# STM32F446x register map
File version: 1.0
Registers are 32-bit, read-write, reset 0x0 unless marked. A register's access mark holds for its fields unless they carry their own. Offsets are from the block's base; [hi:lo] are bit positions; {n}, {i} and the like mark numbered series.

## OTG_FS_PWRCLK — USB on the go full speed
Base 0x50000E00
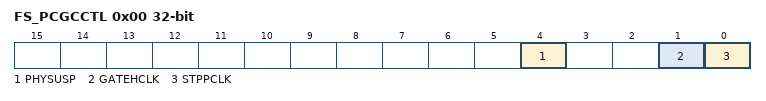
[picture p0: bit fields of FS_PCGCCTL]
0x00 FS_PCGCCTL — OTG_FS power and clock gating control register (OTG_FS_PCGCCTL)
  [4] PHYSUSP — PHY Suspended
  [1] GATEHCLK
  [0] STPPCLK — Stop PHY clock

## NVIC — Nested Vectored Interrupt Controller
Base 0xE000E000
0x04 ICTR ro — Interrupt Controller Type Register
  [3:0] INTLINESNUM — Total number of interrupt lines in groups
{0x100+4i} ISER{i} (i=0..2) — Interrupt Set-Enable Register
  [31:0] SETENA
{0x180+4i} ICER{i} (i=0..2) — Interrupt Clear-Enable Register
  [31:0] CLRENA
{0x200+4i} ISPR{i} (i=0..2) — Interrupt Set-Pending Register
  [31:0] SETPEND
{0x280+4i} ICPR{i} (i=0..2) — Interrupt Clear-Pending Register
  [31:0] CLRPEND
{0x300+4i} IABR{i} ro (i=0..2) — Interrupt Active Bit Register
  [31:0] ACTIVE
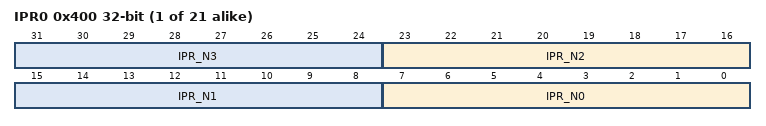
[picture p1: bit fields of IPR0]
{0x400+4i} IPR{i} (i=0..20) — Interrupt Priority Register
  [8n+7:8n] IPR_N{n} (n=0..3)
0xF00 STIR wo — Software Triggered Interrupt Register
  [8:0] INTID — interrupt to be triggered

## FLASH
Base 0x40023C00
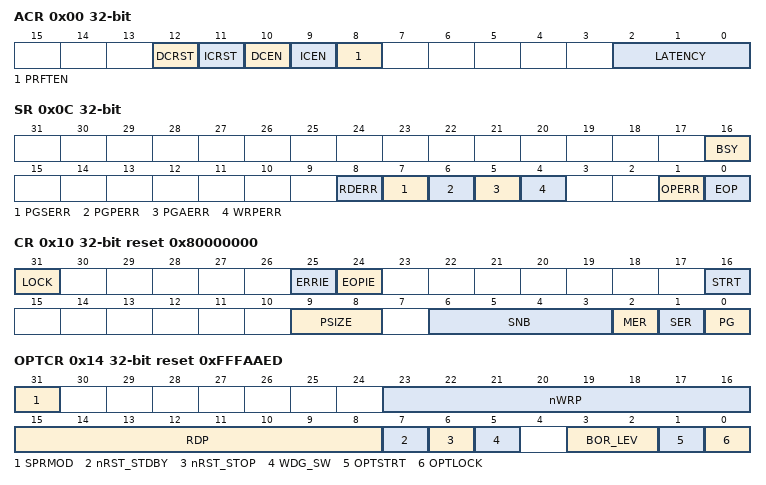
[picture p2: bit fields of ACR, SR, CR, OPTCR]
0x00 ACR access per field — Flash access control register
  [12] DCRST rw — Data cache reset
  [11] ICRST wo — Instruction cache reset
  [10] DCEN rw — Data cache enable
  [9] ICEN rw — Instruction cache enable
  [8] PRFTEN rw — Prefetch enable
  [2:0] LATENCY rw
0x04 KEYR wo — Flash key register
  [31:0] KEY — FPEC key
0x08 OPTKEYR wo — Flash option key register
  [31:0] OPTKEY — Option byte key
0x0C SR access per field — Status register
  [16] BSY ro — Busy
  [8] RDERR rw — Read Protection Error
  [7] PGSERR rw — Programming sequence error
  [6] PGPERR rw — Programming parallelism error
  [5] PGAERR rw — Programming alignment error
  [4] WRPERR rw — Write protection error
  [1] OPERR rw — Operation error
  [0] EOP rw — End of operation
0x10 CR reset 0x80000000 — Control register
  [31] LOCK
  [25] ERRIE — Error interrupt enable
  [24] EOPIE — End of operation interrupt enable
  [16] STRT — Start
  [9:8] PSIZE — Program size
  [6:3] SNB — Sector number
  [2] MER — Mass Erase of sectors 0 to 11
  [1] SER — Sector Erase
  [0] PG — Programming
0x14 OPTCR reset 0xFFFAAED — Flash option control register
  [31] SPRMOD — Selection of Protection Mode of nWPRi bits
  [23:16] nWRP — Not write protect
  [15:8] RDP — Read protect
  [7] nRST_STDBY — nRST_STDBY User option bytes
  [6] nRST_STOP — nRST_STOP User option bytes
  [5] WDG_SW — WDG_SW User option bytes
  [3:2] BOR_LEV — BOR reset Level
  [1] OPTSTRT — Option start
  [0] OPTLOCK — Option lock

## EXTI — External interrupt/event controller
Base 0x40013C00
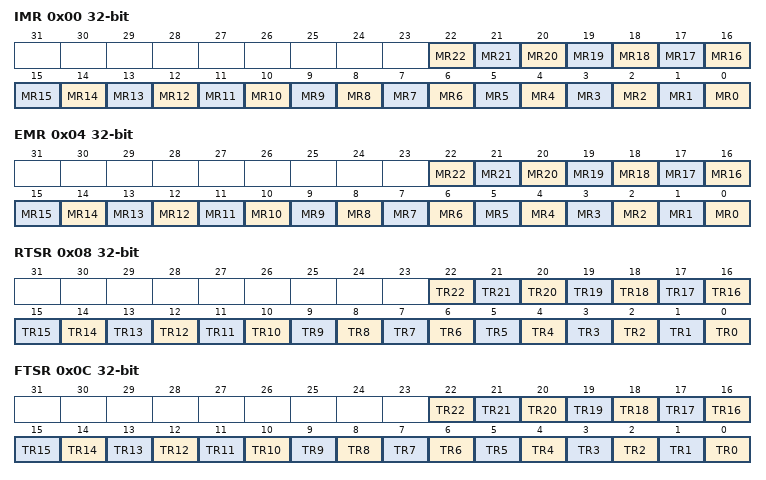
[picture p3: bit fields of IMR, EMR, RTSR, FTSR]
0x00 IMR — Interrupt mask register (EXTI_IMR)
  [n] MR{n} (n=0..22) — Interrupt Mask on line {n}
0x04 EMR — Event mask register (EXTI_EMR)
  [n] MR{n} (n=0..22) — Event Mask on line {n}
0x08 RTSR — Rising Trigger selection register (EXTI_RTSR)
  [n] TR{n} (n=0..22) — Rising trigger event configuration of line {n}
0x0C FTSR — Falling Trigger selection register (EXTI_FTSR)
  [n] TR{n} (n=0..22) — Falling trigger event configuration of line {n}
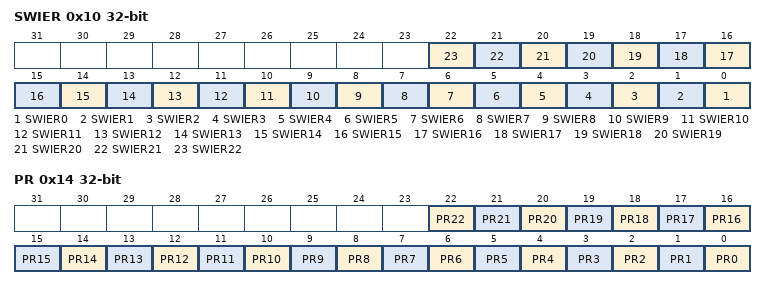
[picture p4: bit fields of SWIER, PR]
0x10 SWIER — Software interrupt event register (EXTI_SWIER)
  [n] SWIER{n} (n=0..22) — Software Interrupt on line {n}
0x14 PR — Pending register (EXTI_PR)
  [n] PR{n} (n=0..22) — Pending bit {n}

## OTG_HS_PWRCLK — USB on the go high speed
Base 0x40040E00
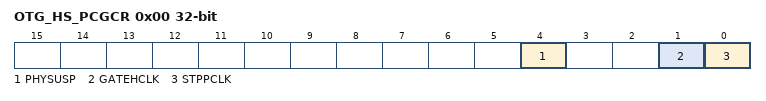
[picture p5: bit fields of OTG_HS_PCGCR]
0x00 OTG_HS_PCGCR — Power and clock gating control register
  [4] PHYSUSP — PHY suspended
  [1] GATEHCLK
  [0] STPPCLK — Stop PHY clock

## PWR — Power control
Base 0x40007000
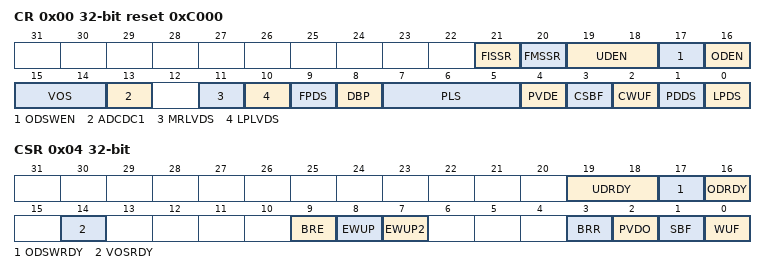
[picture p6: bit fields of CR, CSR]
0x00 CR reset 0xC000 — power control register
  [21] FISSR — Flash Interface Stop while System Run
  [20] FMSSR — Flash Memory Stop while System Run
  [19:18] UDEN — Under-drive enable in stop mode
  [17] ODSWEN — Over-drive switching enabled
  [16] ODEN — Over-drive enable
  [15:14] VOS — Regulator voltage scaling output selection
  [13] ADCDC1
  [11] MRLVDS — Main regulator low voltage in deepsleep mode
  [10] LPLVDS — Low-Power Regulator Low Voltage in deepsleep
  [9] FPDS — Flash power down in Stop mode
  [8] DBP — Disable backup domain write protection
  [7:5] PLS — PVD level selection
  [4] PVDE — Power voltage detector enable
  [3] CSBF — Clear standby flag
  [2] CWUF — Clear wakeup flag
  [1] PDDS — Power down deepsleep
  [0] LPDS — Low-power deep sleep
0x04 CSR access per field — power control/status register
  [19:18] UDRDY rw — Under-drive ready flag
  [17] ODSWRDY ro — Over-drive mode switching ready
  [16] ODRDY ro — Over-drive mode ready
  [14] VOSRDY ro — Regulator voltage scaling output selection ready bit
  [9] BRE rw — Backup regulator enable
  [8] EWUP rw — Enable WKUP pin
  [7] EWUP2 rw — Enable WKUP2 pin
  [3] BRR ro — Backup regulator ready
  [2] PVDO ro — PVD output
  [1] SBF ro — Standby flag
  [0] WUF ro — Wakeup flag
